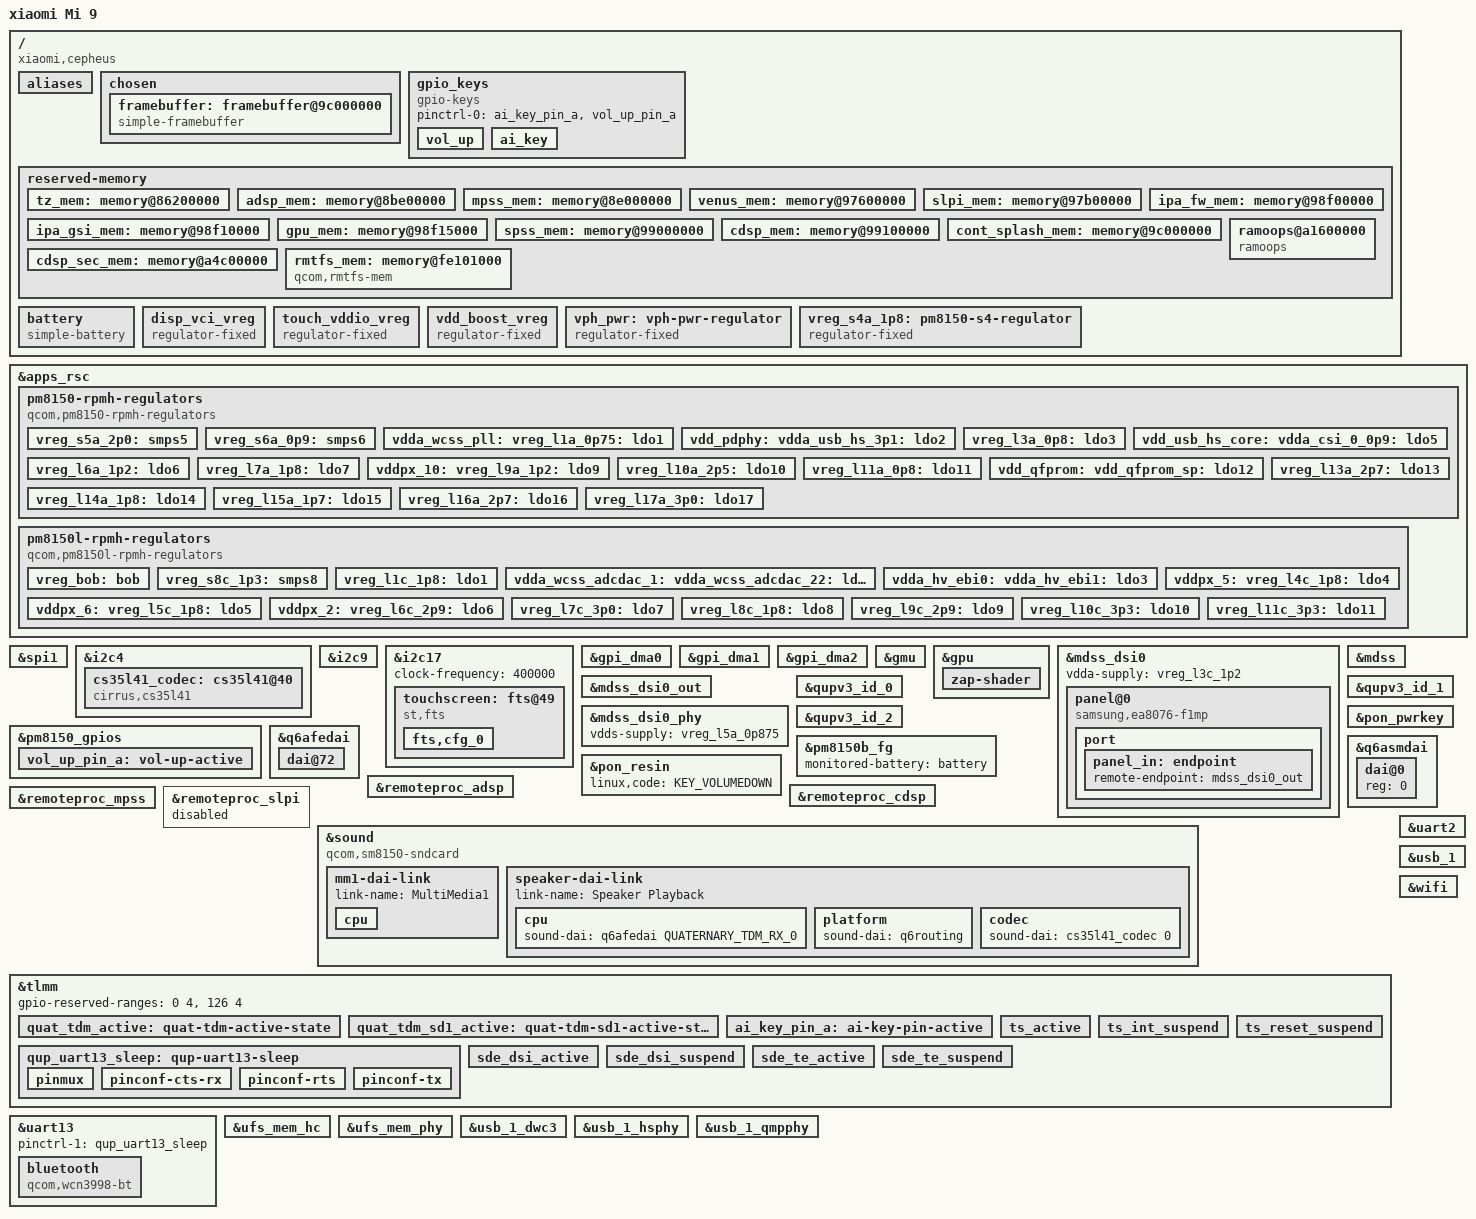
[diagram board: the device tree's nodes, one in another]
// SPDX-License-Identifier: BSD-3-Clause
/*
 * Copyright (c) 2024, Zeyan Li <qaz6750@outlook.com>
 */

/dts-v1/;

#include <dt-bindings/gpio/gpio.h>
#include <dt-bindings/input/input.h>
#include <dt-bindings/input/gpio-keys.h>
#include <dt-bindings/pinctrl/qcom,pmic-gpio.h>
#include <dt-bindings/regulator/qcom,rpmh-regulator.h>
#include <dt-bindings/sound/qcom,q6asm.h>
#include "sm8150.dtsi"
#include "pm8150.dtsi"
#include "pm8150b.dtsi"
#include "pm8150l.dtsi"

/* 
 * Rewrite reserved memory maps inherited from sm8150.dtsi to match the ones
 * used on xiaomi-cepheus.
 * Note: this list is ordered by its memory address in sm8150.dtsi.
 */
/delete-node/ &tz_mem;      /* same address but larger, no place for rmtfs_mem! */
/delete-node/ &rmtfs_mem;   /* moved to completely different address */
/delete-node/ &adsp_mem;    /* same start address, but larger size */
/delete-node/ &mpss_mem;    /* same size, shifted higher, due to larger adsp_mem */
/delete-node/ &venus_mem;   /* same size, shifted higher */
/delete-node/ &slpi_mem;    /* same size, shifted higher */
/delete-node/ &ipa_fw_mem;  /* same size, shifted higher */
/delete-node/ &ipa_gsi_mem; /* same size, shifted higher */
/delete-node/ &gpu_mem;     /* same size, shifted higher */
/delete-node/ &spss_mem;    /* same size, shifted higher */
/delete-node/ &cdsp_mem;    /* same size, shifted higher */

/ {
	model = "xiaomi Mi 9";
	compatible = "xiaomi,cepheus", "qcom,sm8150-cdp", "qcom,sm8150";
	qcom,msm-id = <339 0x20000>;
	qcom,pmic-name = "PM8150";
	qcom,board-id = <37 0>;

	aliases {
		serial0 = &uart2;
		display0 = &framebuffer;
		hsuart0 = &uart13;
		wifi0 = &wifi;
	};

	chosen {
		#address-cells = <2>;
		#size-cells = <2>;
		ranges;

		framebuffer: framebuffer@9c000000 {
			compatible = "simple-framebuffer";
			reg = <0 0x9c000000 0 0x2400000>;
			status = "okay";
			width = <1080>;
			height = <2340>;
			stride = <(1080 * 4)>;
			format = "a8r8g8b8";
			clocks =	<&gcc GCC_DISP_HF_AXI_CLK>,
						<&gcc GCC_DISP_SF_AXI_CLK>;
		};
	};

	gpio_keys {
		compatible = "gpio-keys";
		pinctrl-names = "default";
		pinctrl-0 = <&ai_key_pin_a &vol_up_pin_a>;

		vol_up {
			label = "volume_up";
			gpios = <&pm8150_gpios 6 GPIO_ACTIVE_LOW>;
			linux,input-type = <EV_KEY>;
			linux,code = <KEY_VOLUMEUP>;
			wakeup-source;
			debounce-interval = <15>;
		};

		ai_key {
			label = "ai_key";
			gpios = <&tlmm 97 GPIO_ACTIVE_LOW>;
			linux,input-type = <EV_KEY>;
			linux,code = <KEY_HOMEPAGE>; /* no AI key in Linux */
			wakeup-source;
			debounce-interval = <39>;
		};	};

	reserved-memory {
		tz_mem: memory@86200000 {
			no-map;
			reg = <0x0 0x86200000 0x0 0x5500000>;
		};

		adsp_mem: memory@8be00000 {
			no-map;
			reg = <0x0 0x8be00000 0x0 0x2200000>;
		};

		mpss_mem: memory@8e000000 {
			no-map;
			reg = <0x0 0x8e000000 0x0 0x9600000>;
		};

		venus_mem: memory@97600000 {
			no-map;
			reg = <0x0 0x97600000 0x0 0x500000>;
		};

		slpi_mem: memory@97b00000 {
			no-map;
			reg = <0x0 0x97b00000 0x0 0x1400000>;
		};

		ipa_fw_mem: memory@98f00000 {
			no-map;
			reg = <0x0 0x98f00000 0x0 0x10000>;
		};

		ipa_gsi_mem: memory@98f10000 {
			no-map;
			reg = <0x0 0x98f10000 0x0 0x5000>;
		};

		gpu_mem: memory@98f15000 {
			no-map;
			reg = <0x0 0x98f15000 0x0 0x2000>;
		};

		spss_mem: memory@99000000 {
			no-map;
			reg = <0x0 0x99000000 0x0 0x100000>;
		};

		cdsp_mem: memory@99100000 {
			no-map;
			reg = <0x0 0x99100000 0x0 0x1400000>;
		};

		cont_splash_mem: memory@9c000000 {
			reg = <0x0 0x9c000000 0x0 0x2400000>;
			no-map;
		};

		cdsp_sec_mem: memory@a4c00000 {
			reg = <0x0 0xa4c00000 0x0 0x3c00000>;
			no-map;
		};

		ramoops@a1600000 {
			compatible = "ramoops";
			reg = <0x0 0xa1600000 0x0 0x800000>;
			console-size = <0x400000>;
			ecc-size = <0>;
			ftrace-size = <0>;
			pmsg-size = <0x200000>;
			record-size = <0>;
			no-map;
		};

		rmtfs_mem: memory@fe101000 {
			compatible = "qcom,rmtfs-mem";
			reg = <0 0xfe101000 0 0x300000>;
			no-map;

			qcom,client-id = <1>;
			qcom,vmid = <15>;
		};
	};

	battery: battery {
		compatible = "simple-battery";
		charge-full-design-microamp-hours = <8720000>;
		energy-full-design-microwatt-hours = <33600000>;
		voltage-min-design-microvolt = <3400000>;
		voltage-max-design-microvolt = <4480000>;
	};

	disp_vci_vreg: disp_vci_vreg {
		compatible = "regulator-fixed";
		regulator-name = "disp_vci_vreg";
		enable-active-high;
		regulator-boot-on;
		gpio = <&tlmm 21 0>;
	};

	touch_vddio_vreg: touch_vddio_vreg {
		compatible = "regulator-fixed";
		regulator-name = "disp_vddio_vreg";
		startup-delay-us = <4000>;
		enable-active-high;
		regulator-boot-on;
		gpio = <&tlmm 84 0>;
	};

	vdd_boost_vreg: vdd_boost_vreg {
		compatible = "regulator-fixed";
		regulator-name = "vdd_boost_vreg";
		startup-delay-us = <4000>;
		enable-active-high;
		regulator-always-on;
		gpio = <&pm8150b_gpios 5 0>;
	};

	vph_pwr: vph-pwr-regulator {
		compatible = "regulator-fixed";
		regulator-name = "vph_pwr";
		regulator-min-microvolt = <3700000>;
		regulator-max-microvolt = <3700000>;
	};

	/* S4 is modeled as a fixed regulator in vendor sources */
	vreg_s4a_1p8: pm8150-s4-regulator {
		compatible = "regulator-fixed";
		regulator-name = "vreg_s4a_1p8";

		regulator-min-microvolt = <1800000>;
		regulator-max-microvolt = <1800000>;

		regulator-always-on;
		regulator-boot-on;

		vin-supply = <&vph_pwr>;
	};
};

&apps_rsc {
	pm8150-rpmh-regulators {
		compatible = "qcom,pm8150-rpmh-regulators";
		qcom,pmic-id = "a";

		vdd-s1-supply = <&vph_pwr>;
		vdd-s2-supply = <&vph_pwr>;
		vdd-s3-supply = <&vph_pwr>;
		vdd-s4-supply = <&vph_pwr>;
		vdd-s5-supply = <&vph_pwr>;
		vdd-s6-supply = <&vph_pwr>;
		vdd-s7-supply = <&vph_pwr>;
		vdd-s8-supply = <&vph_pwr>;
		vdd-s9-supply = <&vph_pwr>;
		vdd-s10-supply = <&vph_pwr>;

		vdd-l1-l8-l11-supply = <&vreg_s6a_0p9>;
		vdd-l2-l10-supply = <&vreg_bob>;
		vdd-l3-l4-l5-l18-supply = <&vreg_s6a_0p9>;
		vdd-l6-l9-supply = <&vreg_s8c_1p3>;
		vdd-l7-l12-l14-l15-supply = <&vreg_s5a_2p0>;
		vdd-l13-l16-l17-supply = <&vreg_bob>;

		vreg_s5a_2p0: smps5 {
			regulator-min-microvolt = <1904000>;
			regulator-max-microvolt = <2000000>;
		};

		vreg_s6a_0p9: smps6 {
			regulator-min-microvolt = <920000>;
			regulator-max-microvolt = <1128000>;
		};

		vdda_wcss_pll:
		vreg_l1a_0p75: ldo1 {
			regulator-min-microvolt = <752000>;
			regulator-max-microvolt = <752000>;
			regulator-initial-mode = <RPMH_REGULATOR_MODE_HPM>;
		};

		vdd_pdphy:
		vdda_usb_hs_3p1:
		vreg_l2a_3p1: ldo2 {
			regulator-min-microvolt = <3072000>;
			regulator-max-microvolt = <3072000>;
			regulator-initial-mode = <RPMH_REGULATOR_MODE_HPM>;
		};

		vreg_l3a_0p8: ldo3 {
			regulator-min-microvolt = <480000>;
			regulator-max-microvolt = <932000>;
			regulator-initial-mode = <RPMH_REGULATOR_MODE_HPM>;
		};

		vdd_usb_hs_core:
		vdda_csi_0_0p9:
		vdda_csi_1_0p9:
		vdda_csi_2_0p9:
		vdda_csi_3_0p9:
		vdda_dsi_0_0p9:
		vdda_dsi_1_0p9:
		vdda_dsi_0_pll_0p9:
		vdda_dsi_1_pll_0p9:
		vdda_pcie_1ln_core:
		vdda_pcie_2ln_core:
		vdda_pll_hv_cc_ebi01:
		vdda_pll_hv_cc_ebi23:
		vdda_qrefs_0p875_5:
		vdda_sp_sensor:
		vdda_ufs_2ln_core_1:
		vdda_ufs_2ln_core_2:
		vdda_usb_ss_dp_core_1:
		vdda_usb_ss_dp_core_2:
		vdda_qlink_lv:
		vdda_qlink_lv_ck:
		vreg_l5a_0p875: ldo5 {
			regulator-min-microvolt = <880000>;
			regulator-max-microvolt = <880000>;
			regulator-initial-mode = <RPMH_REGULATOR_MODE_HPM>;
		};

		vreg_l6a_1p2: ldo6 {
			regulator-min-microvolt = <1200000>;
			regulator-max-microvolt = <1200000>;
			regulator-initial-mode = <RPMH_REGULATOR_MODE_HPM>;
		};

		vreg_l7a_1p8: ldo7 {
			regulator-min-microvolt = <1800000>;
			regulator-max-microvolt = <1800000>;
			regulator-initial-mode = <RPMH_REGULATOR_MODE_HPM>;
		};

		vddpx_10:
		vreg_l9a_1p2: ldo9 {
			regulator-min-microvolt = <1200000>;
			regulator-max-microvolt = <1200000>;
			regulator-initial-mode = <RPMH_REGULATOR_MODE_HPM>;
		};

		vreg_l10a_2p5: ldo10 {
			regulator-min-microvolt = <2504000>;
			regulator-max-microvolt = <2960000>;
			regulator-initial-mode = <RPMH_REGULATOR_MODE_HPM>;
		};

		vreg_l11a_0p8: ldo11 {
			regulator-min-microvolt = <800000>;
			regulator-max-microvolt = <800000>;
			regulator-initial-mode = <RPMH_REGULATOR_MODE_HPM>;
		};

		vdd_qfprom:
		vdd_qfprom_sp:
		vdda_apc_cs_1p8:
		vdda_gfx_cs_1p8:
		vdda_usb_hs_1p8:
		vdda_qrefs_vref_1p8:
		vddpx_10_a:
		vreg_l12a_1p8: ldo12 {
			regulator-min-microvolt = <1800000>;
			regulator-max-microvolt = <1800000>;
			regulator-initial-mode = <RPMH_REGULATOR_MODE_HPM>;
		};

		vreg_l13a_2p7: ldo13 {
			regulator-min-microvolt = <2704000>;
			regulator-max-microvolt = <2704000>;
			regulator-initial-mode = <RPMH_REGULATOR_MODE_HPM>;
		};

		vreg_l14a_1p8: ldo14 {
			regulator-min-microvolt = <1880000>;
			regulator-max-microvolt = <1880000>;
			regulator-initial-mode = <RPMH_REGULATOR_MODE_HPM>;
		};

		vreg_l15a_1p7: ldo15 {
			regulator-min-microvolt = <1704000>;
			regulator-max-microvolt = <1704000>;
			regulator-initial-mode = <RPMH_REGULATOR_MODE_HPM>;
		};

		vreg_l16a_2p7: ldo16 {
			regulator-min-microvolt = <2704000>;
			regulator-max-microvolt = <2960000>;
			regulator-initial-mode = <RPMH_REGULATOR_MODE_HPM>;
		};

		vreg_l17a_3p0: ldo17 {
			regulator-min-microvolt = <2856000>;
			regulator-max-microvolt = <3008000>;
			regulator-initial-mode = <RPMH_REGULATOR_MODE_HPM>;
		};
	};

	pm8150l-rpmh-regulators {
		compatible = "qcom,pm8150l-rpmh-regulators";
		qcom,pmic-id = "c";

		vdd-s1-supply = <&vph_pwr>;
		vdd-s2-supply = <&vph_pwr>;
		vdd-s3-supply = <&vph_pwr>;
		vdd-s4-supply = <&vph_pwr>;
		vdd-s5-supply = <&vph_pwr>;
		vdd-s6-supply = <&vph_pwr>;
		vdd-s7-supply = <&vph_pwr>;
		vdd-s8-supply = <&vph_pwr>;

		vdd-l1-l8-supply = <&vreg_s4a_1p8>;
		vdd-l2-l3-supply = <&vreg_s8c_1p3>;
		vdd-l4-l5-l6-supply = <&vreg_bob>;
		vdd-l7-l11-supply = <&vreg_bob>;
		vdd-l9-l10-supply = <&vreg_bob>;

		vdd-bob-supply = <&vph_pwr>;
		vdd-flash-supply = <&vreg_bob>;
		vdd-rgb-supply = <&vreg_bob>;

		vreg_bob: bob {
			regulator-min-microvolt = <3008000>;
			regulator-max-microvolt = <4000000>;
			regulator-initial-mode = <RPMH_REGULATOR_MODE_AUTO>;
			regulator-allow-bypass;
		};

		vreg_s8c_1p3: smps8 {
			regulator-min-microvolt = <1352000>;
			regulator-max-microvolt = <1352000>;
		};

		vreg_l1c_1p8: ldo1 {
			regulator-min-microvolt = <1800000>;
			regulator-max-microvolt = <1800000>;
			regulator-initial-mode = <RPMH_REGULATOR_MODE_HPM>;
		};

		vdda_wcss_adcdac_1:
		vdda_wcss_adcdac_22:
		vreg_l2c_1p3: ldo2 {
			regulator-min-microvolt = <1304000>;
			regulator-max-microvolt = <1304000>;
			regulator-initial-mode = <RPMH_REGULATOR_MODE_HPM>;
		};

		vdda_hv_ebi0:
		vdda_hv_ebi1:
		vdda_hv_ebi2:
		vdda_hv_ebi3:
		vdda_hv_refgen0:
		vdda_mipi_dsi0_1p2:
		vdda_mipi_dsi1_1p2:
		vdda_qlink_hv_ck:
		vreg_l3c_1p2: ldo3 {
			regulator-min-microvolt = <1200000>;
			regulator-max-microvolt = <1200000>;
			regulator-initial-mode = <RPMH_REGULATOR_MODE_HPM>;
		};

		vddpx_5:
		vreg_l4c_1p8: ldo4 {
			regulator-min-microvolt = <1704000>;
			regulator-max-microvolt = <2928000>;
			regulator-initial-mode = <RPMH_REGULATOR_MODE_HPM>;
		};

		vddpx_6:
		vreg_l5c_1p8: ldo5 {
			regulator-min-microvolt = <1704000>;
			regulator-max-microvolt = <2928000>;
			regulator-initial-mode = <RPMH_REGULATOR_MODE_HPM>;
		};

		vddpx_2:
		vreg_l6c_2p9: ldo6 {
			regulator-min-microvolt = <1800000>;
			regulator-max-microvolt = <2960000>;
			regulator-initial-mode = <RPMH_REGULATOR_MODE_HPM>;
		};

		vreg_l7c_3p0: ldo7 {
			regulator-min-microvolt = <2856000>;
			regulator-max-microvolt = <3104000>;
			regulator-initial-mode = <RPMH_REGULATOR_MODE_HPM>;
		};

		vreg_l8c_1p8: ldo8 {
			regulator-min-microvolt = <1800000>;
			regulator-max-microvolt = <1800000>;
			regulator-initial-mode = <RPMH_REGULATOR_MODE_HPM>;
		};

		vreg_l9c_2p9: ldo9 {
			regulator-min-microvolt = <2704000>;
			regulator-max-microvolt = <2960000>;
			regulator-initial-mode = <RPMH_REGULATOR_MODE_HPM>;
		};

		vreg_l10c_3p3: ldo10 {
			regulator-min-microvolt = <3000000>;
			regulator-max-microvolt = <3312000>;
			regulator-initial-mode = <RPMH_REGULATOR_MODE_HPM>;
		};

		vreg_l11c_3p3: ldo11 {
			regulator-min-microvolt = <3000000>;
			regulator-max-microvolt = <3312000>;
			regulator-initial-mode = <RPMH_REGULATOR_MODE_HPM>;
		};
	};
};

&spi1 {
	status = "okay";

	/* IR LED @ 0  */
};

&i2c4 {
	status = "okay";

	/* Qcom SMB1390 @ 10 */

	cs35l41_codec: cs35l41@40 {
		compatible = "cirrus,cs35l41";
		reg = <0x40>;
		interrupt-parent = <&tlmm>;
		interrupts = <10 IRQ_TYPE_LEVEL_LOW>;
		reset-gpios = <&tlmm 89 GPIO_ACTIVE_HIGH>;
		cirrus,boost-peak-milliamp = <4000>;
		cirrus,boost-ind-nanohenry = <1000>;
		cirrus,boost-cap-microfarad = <15>;
		cirrus,asp-sdout-hiz = <3>;
		cirrus,gpio2-src-select = <4>;
		cirrus,gpio2-output-enable;
		sound-name-prefix = "Speaker";
		#sound-dai-cells = <1>;

	};

	/* IDTP9220 @ 3B  */
};

&i2c9 {
	status = "okay";

	/* NXP SN100T @ 28  */
};

&i2c17 {
	clock-frequency = <400000>;
	status = "okay";

	/* FingerTipS-Touch521 @ 49 */
	touchscreen: fts@49 {
		status = "okay";
		compatible = "st,fts";
		reg = <0x49>;
		interrupt-parent = <&tlmm>;
		interrupts = <122 0x2008>;
		pinctrl-names = "pmx_ts_active", "pmx_ts_suspend";
		pinctrl-0 = <&ts_active>;
		pinctrl-1 = <&ts_int_suspend &ts_reset_suspend>;
		vdd-supply = <&touch_vddio_vreg>;
		avdd-supply = <&vreg_l1c_1p8>;
		fts,pwr-reg-name = "avdd";
		fts,bus-reg-name = "vdd";
		fts,irq-gpio = <&tlmm 122 0x2008>;
		fts,irq-gpio-name = "fts_irq";
		fts,reset-gpio-enable;
		fts,reset-gpio = <&tlmm 12 0x00>;
		fts,reset-gpio-name = "fts_rst";
		fts,irq-flags = <0x2008>; /* IRQF_ONESHOT | IRQF_TRIGGER_LOW */
		fts,x-max = <1080>;
		fts,y-max = <2340>;
		fts,default-fw-name = "st_fts_f1.ftb";
		fts,config-array-size = <1>;
		fts,cfg_0 {
			fts,tp-vendor = <0x48>;
			fts,fw-name = "st_fts_f1.ftb";
			fts,limit-name = "stm_fts_production_limits.csv";
			fts,clicknum-file-name = "fts+sdc";
		};
	};
};

&gpi_dma0 {
	status = "okay";
};

&gpi_dma1 {
	status = "okay";
};

&gpi_dma2 {
	status = "okay";
};

&gmu {
	status = "okay";
};

&gpu {
	status = "okay";

	zap-shader {
		memory-region = <&gpu_mem>;
		firmware-name = "qcom/sm8150/xiaomi/cepheus/a640_zap.mbn";
	};
};

&mdss_dsi0 {
	vdda-supply = <&vreg_l3c_1p2>;
	status = "okay";
	panel@0 {
		compatible = "samsung,ea8076-f1mp";
		reg = <0>;
		status = "okay";

		vddio-supply = <&vreg_l14a_1p8>;
		vcie-supply = <&disp_vci_vreg>;
		vci-supply = <&vreg_l13a_2p7>;
		reset-gpios = <&tlmm 6 GPIO_ACTIVE_LOW>;

		pinctrl-names = "panel_active", "panel_suspend";
		pinctrl-0 = <&sde_dsi_active &sde_te_active>;
		pinctrl-1 = <&sde_dsi_suspend &sde_te_suspend>;

		port {
			panel_in: endpoint {
				remote-endpoint = <&mdss_dsi0_out>;
			};
		};
	};
};

&mdss_dsi0_out {
	data-lanes = <0 1 2 3>;
	remote-endpoint = <&panel_in>;
};

&mdss_dsi0_phy {
	status = "okay";
	vdds-supply = <&vreg_l5a_0p875>;
};

&mdss {
	status = "okay";
};

&qupv3_id_0 {
	status = "okay";
};

&qupv3_id_1 {
	status = "okay";
};

&qupv3_id_2 {
	status = "okay";
};

&pm8150_gpios {
	vol_up_pin_a: vol-up-active {
		pins = "gpio6";
		function = "normal";
		input-enable;
		bias-pull-up;
		qcom,drive-strength = <PMIC_GPIO_STRENGTH_NO>;
	};
};

&pm8150b_fg {
	status = "okay";
	monitored-battery = <&battery>;
};

&pon_pwrkey {
	status = "okay";
};

&pon_resin {
	linux,code = <KEY_VOLUMEDOWN>;
	status = "okay";
};


&q6afedai {
	dai@72 {
		reg = <QUATERNARY_TDM_RX_0>;
		qcom,tdm-sync-mode = <1>;
		qcom,tdm-sync-src = <1>;
		qcom,tdm-data-out = <0>;
		qcom,tdm-invert-sync = <1>;
		qcom,tdm-data-delay = <1>;
		qcom,tdm-data-align = <0>;
	};
};

&q6asmdai {
	dai@0 {
		reg = <0>;
	};
};

&remoteproc_adsp {
	status = "okay";
	firmware-name = "qcom/sm8150/xiaomi/cepheus/adsp.mbn";
};

&remoteproc_cdsp {
	status = "okay";
	firmware-name = "qcom/sm8150/xiaomi/cepheus/cdsp.mbn";
};

&remoteproc_mpss {
	status = "okay";
	firmware-name = "qcom/sm8150/xiaomi/cepheus/modem.mbn";
};

&remoteproc_slpi {
	status = "disabled";
	firmware-name = "qcom/sm8150/xiaomi/cepheus/slpi.mbn";
};

&sound {
	compatible = "qcom,sm8150-sndcard";
	pinctrl-0 = <&quat_tdm_active
		&quat_tdm_sd1_active>;
	pinctrl-names = "default";
	model = "Xiaomi 9";

	audio-routing =
		"MultiMedia1 Playback", "SPK";

	mm1-dai-link {
		link-name = "MultiMedia1";
		cpu {
			sound-dai = <&q6asmdai MSM_FRONTEND_DAI_MULTIMEDIA1>;
		};
	};

	speaker-dai-link {
		link-name = "Speaker Playback";
		cpu {
			sound-dai = <&q6afedai QUATERNARY_TDM_RX_0>;
		};

		platform {
			sound-dai = <&q6routing>;
		};

		codec {
			sound-dai = <&cs35l41_codec 0>;
		};
	};
};

&tlmm {
	/* gpios 0..3 are NFC spi, gpios 126..129 are FP spi */
	gpio-reserved-ranges = <0 4>, <126 4>;

	quat_tdm_active: quat-tdm-active-state {
		pins = "gpio137", "gpio138";
		function = "qua_mi2s";
		drive-strength = <8>;
		bias-disable;
		output-high;
	};

	quat_tdm_sd1_active: quat-tdm-sd1-active-state {
		pins = "gpio140";
		function = "qua_mi2s";
		drive-strength = <8>;
		bias-disable;
	};

	ai_key_pin_a: ai-key-pin-active {
		pins = "gpio97";
		function = "gpio";
		drive-strength = <2>;
		bias-pull-up;
		input-enable;
	};

	ts_active: ts_active {
		pins = "gpio122", "gpio12";
		function = "gpio";
		drive-strength = <8>;
		bias-pull-up;
	};

	ts_int_suspend: ts_int_suspend {
		pins = "gpio122";
		function = "gpio";
		drive-strength = <2>;
		input-enable;
		bias-pull-down;
	};

	ts_reset_suspend: ts_reset_suspend {
		pins = "gpio12";
		function = "gpio";
		drive-strength = <2>;
		bias-disable;
		output-low;
	};

	qup_uart13_sleep: qup-uart13-sleep {
		pinmux {
			pins = "gpio43", "gpio44", "gpio46";
			function = "qup13";
		};

		pinconf-cts-rx {
			pins = "gpio43", "gpio46";
			drive-strength = <2>;
			bias-disable;
		};

		pinconf-rts {
			pins = "gpio44";
			drive-strength = <2>;
			bias-pull-down;
		};

		pinconf-tx {
			pins = "gpio45";
			drive-strength = <2>;
			bias-pull-up;
		};
	};

	sde_dsi_active: sde_dsi_active {
		pins = "gpio6", "gpio7", "gpio5";
		function = "gpio";
		drive-strength = <8>;
		bias-disable;
	};

	sde_dsi_suspend: sde_dsi_suspend {
		pins = "gpio6", "gpio7", "gpio5";
		function = "gpio";
		drive-strength = <2>;
		bias-pull-down;
	};

	sde_te_active: sde_te_active {
		pins = "gpio8";
		function = "mdp_vsync";
		drive-strength = <2>;
		bias-pull-down;
	};

	sde_te_suspend: sde_te_suspend {
		pins = "gpio8";
		function = "mdp_vsync";
		drive-strength = <2>;
		bias-pull-down;
	};
};

&uart2 {
	status = "okay";
};

&uart13 {
	status = "okay";

	pinctrl-names = "default", "sleep";
	pinctrl-1 = <&qup_uart13_sleep>;

	bluetooth: bluetooth {
		compatible = "qcom,wcn3998-bt";
		vddio-supply = <&vreg_l1a_0p75>;
		vddxo-supply = <&vreg_l7a_1p8>;
		vddrf-supply = <&vreg_l2c_1p3>;
		vddch0-supply = <&vreg_l11c_3p3>;
		max-speed = <3200000>;
		firmware-name = "cepheus/crnv21.bin";
	};
};

&ufs_mem_hc {
	status = "okay";
};

&ufs_mem_phy {
	status = "okay";
};

&usb_1 {
	status = "okay";
};

&usb_1_dwc3 {
	snps,has-lpm-erratum;
	snps,hird-threshold = /bits/ 8 <0x10>;
	maximum-speed = "high-speed";
	dr_mode = "host";
};

&usb_1_hsphy {
	status = "okay";
	vdda-pll-supply = <&vreg_l5a_0p875>;
	vdda18-supply = <&vreg_l12a_1p8>;
	vdda33-supply = <&vreg_l2a_3p1>;
};

&usb_1_qmpphy {
	status = "okay";
	vdda-phy-supply = <&vreg_l3c_1p2>;
	vdda-pll-supply = <&vreg_l5a_0p875>;
};

&wifi {
	status = "okay";

	vdd-0.8-cx-mx-supply = <&vdda_wcss_pll>;
	vdd-1.8-xo-supply = <&vreg_l7a_1p8>;
	vdd-1.3-rfa-supply = <&vreg_l2c_1p3>;
	vdd-3.3-ch0-supply = <&vreg_l11c_3p3>;
};
